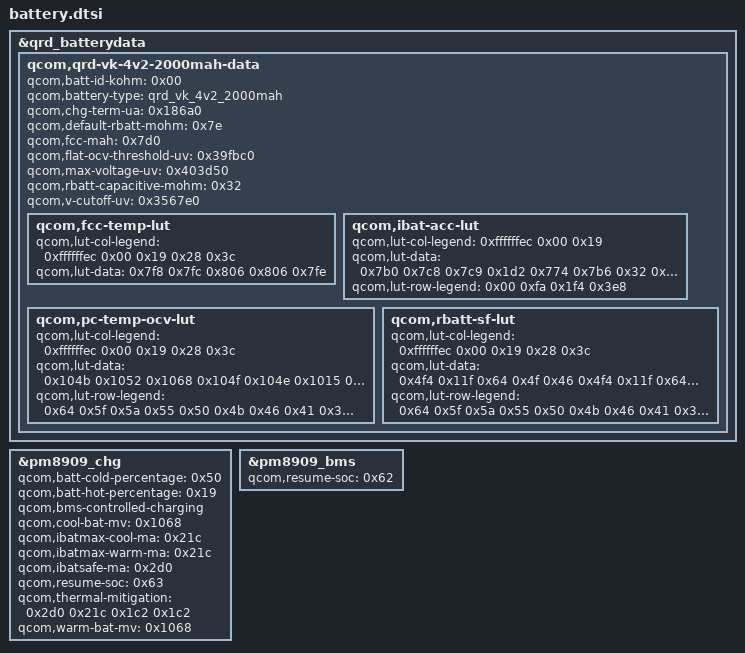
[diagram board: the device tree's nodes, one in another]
&qrd_batterydata {
	/delete-node/ qcom,qrd-skuc-4v2-2000mah-data;

	qcom,qrd-vk-4v2-2000mah-data {
		qcom,batt-id-kohm = <0x00>;
		qcom,battery-type = "qrd_vk_4v2_2000mah";
		qcom,chg-term-ua = <0x186a0>;
		qcom,default-rbatt-mohm = <0x7e>;
		qcom,fcc-mah = <0x7d0>;
		qcom,flat-ocv-threshold-uv = <0x39fbc0>;
		qcom,max-voltage-uv = <0x403d50>;
		qcom,rbatt-capacitive-mohm = <0x32>;
		qcom,v-cutoff-uv = <0x3567e0>;

		qcom,fcc-temp-lut {
			qcom,lut-col-legend = <0xffffffec 0x00 0x19 0x28 0x3c>;
			qcom,lut-data = <0x7f8 0x7fc 0x806 0x806 0x7fe>;
		};

		qcom,ibat-acc-lut {
			qcom,lut-col-legend = <0xffffffec 0x00 0x19>;
			qcom,lut-data = <0x7b0 0x7c8 0x7c9 0x1d2 0x774 0x7b6 0x32 0x6c4 0x7a7 0x06 0x462 0x770>;
			qcom,lut-row-legend = <0x00 0xfa 0x1f4 0x3e8>;
		};

		qcom,pc-temp-ocv-lut {
			qcom,lut-col-legend = <0xffffffec 0x00 0x19 0x28 0x3c>;
			qcom,lut-data = <0x104b 0x1052 0x1068 0x104f 0x104e 0x1015 0x101e 0x101c 0x101a 0x1016 0xfe4 0xfee 0xfed 0xfeb 0xfe8 0xfa9 0xfc0 0xfc2 0xfc0 0xfbc 0xf78 0xf92 0xf9a 0xf99 0xf96 0xf54 0xf70 0xf78 0xf76 0xf72 0xf32 0xf4d 0xf59 0xf58 0xf54 0xf14 0xf2c 0xf3c 0xf3b 0xf37 0xef9 0xf0e 0xf1b 0xf1c 0xf1a 0xee4 0xef5 0xef7 0xef7 0xef4 0xed4 0xee0 0xee0 0xedf 0xedd 0xec6 0xed0 0xed0 0xed0 0xecd 0xeb8 0xec2 0xec5 0xec4 0xec1 0xeaa 0xeb8 0xebc 0xeba 0xeb7 0xe9b 0xeae 0xeb4 0xeaf 0xea8 0xe8a 0xe9e 0xea7 0xe9f 0xe91 0xe76 0xe8c 0xe94 0xe8a 0xe7d 0xe60 0xe7e 0xe7a 0xe73 0xe66 0xe4c 0xe74 0xe64 0xe5b 0xe50 0xe3c 0xe6c 0xe5f 0xe57 0xe4b 0xe31 0xe68 0xe5d 0xe55 0xe4a 0xe25 0xe62 0xe5b 0xe54 0xe48 0xe16 0xe5c 0xe58 0xe50 0xe44 0xe06 0xe52 0xe54 0xe4c 0xe40 0xdf1 0xe43 0xe4a 0xe41 0xe32 0xdd6 0xe28 0xe30 0xe25 0xe14 0xdb2 0xdff 0xe02 0xdf6 0xde4 0xd82 0xdc4 0xdc3 0xdb8 0xda7 0xd3b 0xd6c 0xd6e 0xd64 0xd56 0xcc2 0xce5 0xcf2 0xce8 0xcda 0xbc4 0xbb8 0xbb8 0xbcc 0xbc4>;
			qcom,lut-row-legend = <0x64 0x5f 0x5a 0x55 0x50 0x4b 0x46 0x41 0x3c 0x37 0x32 0x2d 0x28 0x23 0x1e 0x19 0x14 0x10 0x0d 0x0b 0x0a 0x09 0x08 0x07 0x06 0x05 0x04 0x03 0x02 0x01 0x00>;
		};

		qcom,rbatt-sf-lut {
			qcom,lut-col-legend = <0xffffffec 0x00 0x19 0x28 0x3c>;
			qcom,lut-data = <0x4f4 0x11f 0x64 0x4f 0x46 0x4f4 0x11f 0x64 0x4f 0x46 0x504 0x124 0x66 0x51 0x47 0x4ef 0x12d 0x67 0x51 0x49 0x4de 0x12f 0x6b 0x53 0x49 0x4de 0x131 0x70 0x56 0x4b 0x4d5 0x12e 0x76 0x59 0x4d 0x4d4 0x12a 0x7d 0x5f 0x51 0x4d3 0x124 0x7b 0x62 0x54 0x4e2 0x121 0x6a 0x56 0x4b 0x4f0 0x120 0x65 0x51 0x48 0x509 0x122 0x66 0x51 0x49 0x52a 0x127 0x66 0x53 0x4b 0x558 0x12b 0x69 0x56 0x4d 0x59c 0x132 0x6b 0x54 0x4d 0x5f4 0x136 0x6b 0x51 0x49 0x663 0x139 0x6c 0x53 0x4a 0x6cc 0x149 0x6a 0x54 0x4b 0x6fe 0x157 0x67 0x51 0x49 0x729 0x160 0x69 0x52 0x49 0x77a 0x16c 0x6a 0x53 0x4b 0x7f4 0x17b 0x6c 0x56 0x4c 0x8de 0x18d 0x70 0x57 0x4e 0xa48 0x1a5 0x77 0x5a 0x50 0xc6e 0x1c4 0x7a 0x5a 0x4f 0xffe 0x1ef 0x79 0x59 0x4c 0x161c 0x245 0x77 0x5a 0x4f 0x21a8 0x302 0x81 0x5f 0x53 0x3abd 0x512 0x90 0x6a 0x5c 0x7579 0xa25 0xf0 0x98 0x72 0xeaf2 0x144a 0x1df 0x131 0xe5>;
			qcom,lut-row-legend = <0x64 0x5f 0x5a 0x55 0x50 0x4b 0x46 0x41 0x3c 0x37 0x32 0x2d 0x28 0x23 0x1e 0x19 0x14 0x10 0x0d 0x0b 0x0a 0x09 0x08 0x07 0x06 0x05 0x04 0x03 0x02 0x01 0x00>;
		};
	};
};

&pm8909_chg {
	qcom,batt-cold-percentage = <0x50>;
	qcom,batt-hot-percentage = <0x19>;
	qcom,bms-controlled-charging;
	qcom,cool-bat-mv = <0x1068>;
	qcom,ibatmax-cool-ma = <0x21c>;
	qcom,ibatmax-warm-ma = <0x21c>;
	qcom,ibatsafe-ma = <0x2d0>;
	qcom,resume-soc = <0x63>;
	qcom,thermal-mitigation = <0x2d0 0x21c 0x1c2 0x1c2>;
	qcom,warm-bat-mv = <0x1068>;
};

&pm8909_bms {
	qcom,resume-soc = <0x62>;
};
